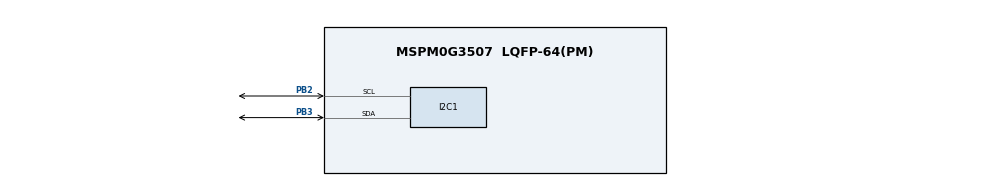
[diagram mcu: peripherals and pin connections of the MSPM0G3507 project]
/**
 * These arguments were used when this file was generated. They will be automatically applied on subsequent loads
 * via the GUI or CLI. Run CLI with '--help' for additional information on how to override these arguments.
 */
//@cliArgs --device "MSPM0G350X" --package "LQFP-64(PM)" --part "Default"
//@v2CliArgs --device "MSPM0G3507" --package "LQFP-64(PM)"
// @cliArgs --board /ti/boards/LP_MSPM0G3507 --rtos nortos

/**
 * Import the modules used in this configuration.
 *
 * BOOSTXL-BASSENSORS sensors:
 *   - HDC2010  (I2C 0x40) - Humidity + Temperature
 *   - TMP116   (I2C 0x48) - Temperature
 *   - OPT3001  (I2C 0x44) - Ambient Light
 *   - DRV5055  (ADC)      - Hall Effect Magnetic
 */

/* ---- GPIO: Sensor power enables ---- */
const GPIO   = scripting.addModule("/ti/driverlib/GPIO", {}, false);
const GPIO1  = GPIO.addInstance();

/* ---- I2C1: Controller mode, PB2(SCL)/PB3(SDA) @ 400kHz ---- */
const I2C    = scripting.addModule("/ti/driverlib/I2C", {}, false);
const I2C1   = I2C.addInstance();

/* ---- ADC12: PA25 (CH2) for DRV5055 Hall sensor ---- */
const ADC12  = scripting.addModule("/ti/driverlib/ADC12", {}, false);
const ADC121 = ADC12.addInstance();

const SYSCTL = scripting.addModule("/ti/driverlib/SYSCTL");
const Board  = scripting.addModule("/ti/driverlib/Board", {}, false);

/**
 * Write custom configuration values to the imported modules.
 */

/* GPIO: HDC2010_EN = PB24 (active low, init LOW), DRV5055_EN = PB15 (active low, init LOW) */
GPIO1.$name                          = "GPIO_SENSOR_EN";
GPIO1.associatedPins.create(2);
GPIO1.associatedPins[0].$name        = "HDC2010_EN";
GPIO1.associatedPins[0].assignedPort = "PORTB";
GPIO1.associatedPins[0].assignedPin  = "24";
GPIO1.associatedPins[0].initialValue = "CLEARED";
GPIO1.associatedPins[1].$name        = "DRV5055_EN";
GPIO1.associatedPins[1].assignedPort = "PORTB";
GPIO1.associatedPins[1].assignedPin  = "15";
GPIO1.associatedPins[1].initialValue = "CLEARED";

/* I2C1 Controller @ 400kHz on PB2(SCL) / PB3(SDA) */
I2C1.$name                     = "I2C1";
I2C1.basicEnableController     = true;
I2C1.basicControllerBusSpeed   = 400000;
I2C1.advAnalogGlitchFilter     = "DISABLED";
I2C1.peripheral.$assign        = "I2C1";
I2C1.peripheral.sdaPin.$assign = "PB3";
I2C1.peripheral.sclPin.$assign = "PB2";

/* ADC12_0: PA25 (CH2), single conversion, manual power down */
ADC121.$name                = "ADC12_0";
ADC121.adcMem0chansel       = "DL_ADC12_INPUT_CHAN_2";
ADC121.sampleTime0          = "62.5ns";
ADC121.repeatMode           = false;
ADC121.powerDownMode        = "DL_ADC12_POWER_DOWN_MODE_MANUAL";
ADC121.peripheral.$assign   = "ADC0";
ADC121.peripheral.adcPin2.$assign = "PA25";

SYSCTL.forceDefaultClkConfig = true;
